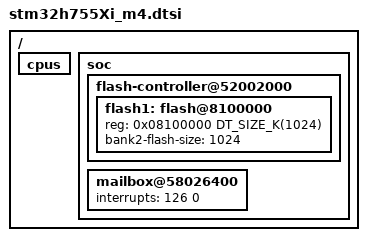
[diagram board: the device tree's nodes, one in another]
/*
 * Copyright (c) 2024 S&C Electric Company <Michael.Banducci@sandc.com>
 *
 * SPDX-License-Identifier: Apache-2.0
 */

#include <st/h7/stm32h755.dtsi>

/delete-node/ &itcm;
/delete-node/ &dtcm;
/delete-node/ &flash0;

/ {
	cpus {
		/delete-node/ cpu@0;
	};

	soc {
		flash-controller@52002000 {
			flash1: flash@8100000 {
				reg = <0x08100000 DT_SIZE_K(1024)>;
				bank2-flash-size = <1024>;
			};
		};

		mailbox@58026400 {
			interrupts = <126 0>;
		};
	};
};
